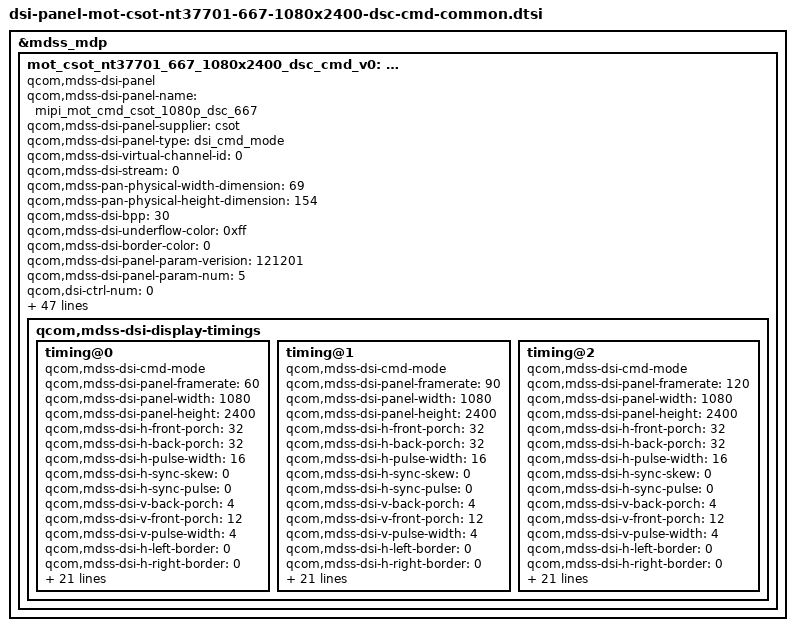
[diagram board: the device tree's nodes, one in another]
/* Copyright (c) 2019-2020, The Linux Foundation. All rights reserved.
 *
 * This program is free software; you can redistribute it and/or modify
 * it under the terms of the GNU General Public License version 2 and
 * only version 2 as published by the Free Software Foundation.
 *
 * This program is distributed in the hope that it will be useful,
 * but WITHOUT ANY WARRANTY; without even the implied warranty of
 * MERCHANTABILITY or FITNESS FOR A PARTICULAR PURPOSE.  See the
 * GNU General Public License for more details.
 */
&mdss_mdp {
mot_csot_nt37701_667_1080x2400_dsc_cmd_v0: qcom,mdss_dsi_mot_csot_nt37701_667_1080x2400_dsc_cmd_v0 {
compatible = "qcom,mdss-dsi-panel";
qcom,mdss-dsi-panel-name = "mipi_mot_cmd_csot_1080p_dsc_667";
qcom,mdss-dsi-panel-supplier = "csot";
qcom,mdss-dsi-panel-type = "dsi_cmd_mode";
qcom,mdss-dsi-virtual-channel-id = <0>;
qcom,mdss-dsi-stream = <0>;
qcom,mdss-pan-physical-width-dimension = <69>;
qcom,mdss-pan-physical-height-dimension = <154>;
qcom,mdss-dsi-bpp = <30>;
qcom,mdss-dsi-underflow-color = <0xff>;
qcom,mdss-dsi-border-color = <0>;
qcom,mdss-dsi-panel-param-verision = <121201>;
qcom,mdss-dsi-panel-param-num = <5>;

qcom,dsi-ctrl-num = <0>;
qcom,dsi-phy-num = <0>;

qcom,mdss-dsi-traffic-mode = "burst_mode";
qcom,mdss-dsi-bllp-eof-power-mode;
qcom,mdss-dsi-bllp-power-mode;
qcom,mdss-dsi-lane-0-state;
qcom,mdss-dsi-lane-1-state;
qcom,mdss-dsi-lane-2-state;
qcom,mdss-dsi-lane-3-state;

qcom,mdss-dsi-dma-trigger = "trigger_sw";
qcom,mdss-dsi-mdp-trigger = "none";
qcom,mdss-dsi-reset-sequence = <0 11>, <1 1>, <0 1>, <1 11>;
qcom,mdss-dsi-lp11-init;
qcom,mdss-dsi-tx-eot-append;
qcom,mdss-dsi-te-pin-select = <1>;
qcom,mdss-dsi-te-dcs-command = <1>;

qcom,mdss-dsi-te-using-te-pin;

qcom,bklt-dcs-2bytes-enabled;
qcom,mdss-dsi-bl-min-level = <3>;
qcom,mdss-dsi-bl-max-level = <2047>;
qcom,mdss-dsi-bl-pmic-control-type = "bl_ctrl_dcs";

qcom,mdss-dsi-panel-hdr-enabled;
qcom,mdss-dsi-panel-hdr-color-primaries = <14500 15500 32000
	        17000 15500 30000 8000 3000>;
qcom,mdss-dsi-panel-peak-brightness = <4200000>;

qcom,mdss-dsi-panel-blackness-level = <3230>;
qcom,mdss-dsi-hbm-on-command = [
		39 01 00 00 00 00 03 51 0F FF];
qcom,mdss-dsi-hbm-off-command = [
		39 01 00 00 00 00 03 51 07 FF];

qcom,mdss-dsi-color-vbt-command = [
                15 01 00 00 00 00 02 55 90];
qcom,mdss-dsi-color-vbt-command-state = "dsi_lp_mode";
qcom,mdss-dsi-color-std-command = [
                15 01 00 00 00 00 02 55 90];
qcom,mdss-dsi-color-std-command-state = "dsi_lp_mode";
qcom,mdss-dsi-color-game-command = [
		15 01 00 00 00 00 02 55 80];
qcom,mdss-dsi-color-game-command-state = "dsi_lp_mode";
qcom,mdss-dsi-color-none-command = [
		15 01 00 00 00 00 02 55 90];
qcom,mdss-dsi-color-none-command-state = "dsi_lp_mode";

//qcom,mdss-dsi-acl-on-command = [
//		39 01 00 00 00 00 06 F0 55 AA 52 08 00
//		15 00 00 00 00 00 02 B0 0C
//		15 01 00 00 00 00 02 55 05];
//qcom,mdss-dsi-acl-off-command = [
//		15 01 00 00 00 00 02 55 00];


qcom,mdss-dsi-display-timings {
	timing@0{
		qcom,mdss-dsi-cmd-mode;
		qcom,mdss-dsi-panel-framerate = <60>;
		qcom,mdss-dsi-panel-width = <1080>;
		qcom,mdss-dsi-panel-height = <2400>;
		qcom,mdss-dsi-h-front-porch = <32>;
		qcom,mdss-dsi-h-back-porch = <32>;
		qcom,mdss-dsi-h-pulse-width = <16>;
		qcom,mdss-dsi-h-sync-skew = <0>;
		qcom,mdss-dsi-h-sync-pulse = <0>;
		qcom,mdss-dsi-v-back-porch = <4>;
		qcom,mdss-dsi-v-front-porch = <12>;
		qcom,mdss-dsi-v-pulse-width = <4>;
		qcom,mdss-dsi-h-left-border = <0>;
		qcom,mdss-dsi-h-right-border = <0>;
		qcom,mdss-dsi-v-top-border = <0>;
		qcom,mdss-dsi-v-bottom-border = <0>;
		qcom,mdss-dsi-panel-jitter = <0x20 0xa>; /* 90fps +/- 2 */
		qcom,mdss-dsi-timing-switch-command = [
			15 01 00 00 14 00 02 2F 01 //01:60 02:90 03:120
			15 01 00 00 00 00 02 8B 00
		];

		qcom,mdss-dsi-on-command = [
                        39 01 00 00 00 00 06 F0 55 AA 52 08 07
                        39 01 00 00 00 00 02 6F 00
                        39 01 00 00 00 00 16 C5 21 00 03 49 03 49 00 00 3F FF 41 76 3F FF 41 76 00 00 0A CA D1
                        39 01 00 00 00 00 02 6F 15
                        39 01 00 00 00 00 10 C5 01 FE 15 02 1B 32 33 80 03 49 0F E3 E3 00 00
                        39 01 00 00 00 00 02 6F 24
                        39 01 00 00 00 00 08 C5 00 00 00 00 00 00 00
                        39 01 00 00 00 00 02 6F 00
                        39 01 00 00 00 00 16 C6 27 00 03 49 03 49 00 00 00 00 00 00 3F FF 41 76 00 00 00 00 00
                        39 01 00 00 00 00 02 6F 15
                        39 01 00 00 00 00 10 C6 02 1C 15 02 39 32 33 80 00 00 03 1D E3 00 00
                        39 01 00 00 00 00 02 6F 24
                        39 01 00 00 00 00 08 C6 00 00 00 00 00 00 00
                        39 01 00 00 00 00 02 6F 00
                        39 01 00 00 00 00 16 C7 2D 00 03 84 03 49 00 00 3F FF 34 18 00 00 00 00 80 00 00 00 00
                        39 01 00 00 00 00 02 6F 15
                        39 01 00 00 00 00 10 C7 01 FE 33 02 1B 51 33 50 00 00 0C E2 1D 00 00
                        39 01 00 00 00 00 02 6F 24
                        39 01 00 00 00 00 08 C7 00 00 00 00 00 00 00
                        39 01 00 00 00 00 02 6F 00
                        39 01 00 00 00 00 16 C8 2B 00 03 84 03 49 00 00 00 00 00 00 00 00 00 00 FF FF F4 73 5C
                        39 01 00 00 00 00 02 6F 15
                        39 01 00 00 00 00 10 C8 02 1C 33 02 39 51 33 5F FC 9A 00 1E 1D 00 00
                        39 01 00 00 00 00 02 6F 24
                        39 01 00 00 00 00 08 C8 00 00 00 00 00 00 00

                        39 01 00 00 00 00 06 F0 55 AA 52 08 00
                        39 01 00 00 00 00 02 6F 02
                        39 01 00 00 00 00 03 EC 81 C2
			39 01 00 00 00 00 19 CC 40 54 5A 60 66 6A 6C 6C 68 62 5B 53 4D 48 44 41 40 50 60 70 58 68 74 74
			39 01 00 00 00 00 12 CD 40 40 40 40 40 40 40 40 40 45 49 4C 4B 48 44 41 40
			39 01 00 00 00 00 13 CE 00 40 40 40 40 40 40 40 40 40 40 40 40 40 40 40 40 40
			39 01 00 00 00 00 12 CF 40 40 40 40 40 40 40 40 40 40 40 40 40 40 40 40 40
			39 01 00 00 00 00 07 D0 00 00 FC 74 0C 1D
			39 01 00 00 00 00 2E D1 50 50 50 50 50 50 50 50 50 50 50 50 50 50 50 50 50 50 50 50 50 50 50 50 00 00 00 00 00 00 00 00 00 00 00 00 00 06 0C 03 09 0F 68 88 00
			39 01 00 00 00 00 07 D3 30 52 74 74 50 10
			39 01 00 00 00 00 1A D4 0F 77 74 0F 00 14 0F 18 1F 05 0D 14 03 07 0A A0 75 FA 10 44 12 00 00 80 00
			39 01 00 00 00 00 14 D7 30 40 40 40 40 40 40 40 40 40 40 40 40 40 40 40 40 40 40
			39 01 00 00 00 00 02 55 90
			39 01 00 00 00 00 06 F0 55 AA 52 08 07
			39 01 00 00 00 00 03 c0 01 0f

			39 01 00 00 00 00 06 F0 55 AA 52 08 01
			39 01 00 00 00 00 02 6f 01
			39 01 00 00 00 00 02 cd 81

			39 01 00 00 00 00 06 F0 55 AA 52 08 08
			39 01 00 00 00 00 03 C0 0F 7E//demura scale

			15 01 00 00 00 00 02 03 01
			15 01 00 00 00 00 02 90 01
			39 01 00 00 00 00 13 91 AB 28 00 0C C2 00 03 1C 01 7E 00 0F 08 BB 04 3D 10 F0
			15 01 00 00 00 00 02 2C 00 //dsc config 10bit

			39 01 00 00 00 00 03 51 00 00
			15 01 00 00 00 00 02 53 20
			15 01 00 00 00 00 02 35 00 //te enable

			39 01 00 00 00 00 05 2A 00 00 04 37
			39 01 00 00 00 00 05 2B 00 00 09 5F

			15 01 00 00 00 00 02 2F 01 //01:60 02:90 03:120
			15 01 00 00 00 00 02 8B 00

			05 01 00 00 6e 00 01 11
			05 01 00 00 00 00 01 29];	/* display on */
		qcom,mdss-dsi-off-command = [
			05 01 00 00 00 00 01 28		/* display_off */
			05 01 00 00 78 00 01 10];	/* enter sleep mode */

		qcom,mdss-dsi-on-command-state = "dsi_lp_mode";
		qcom,mdss-dsi-off-command-state = "dsi_lp_mode";
		qcom,mdss-dsi-timing-switch-command-state =
			"dsi_lp_mode";
		qcom,compression-mode = "dsc";
		/* Why QCOM doesn't use this, even it used 2 encoder
		 * as for that dsi_sw43404_amoled_cmd, for ex */
		/* qcom,mdss-dsc-encoders = <2>; */
		qcom,mdss-dsc-version = <0x11>;
		qcom,mdss-dsc-slice-height = <12>;
		qcom,mdss-dsc-slice-width = <1080>;
		qcom,mdss-dsc-slice-per-pkt = <1>;
		qcom,mdss-dsc-bit-per-component = <10>;
		qcom,mdss-dsc-bit-per-pixel = <8>;
		qcom,mdss-dsc-block-prediction-enable;
	};

	timing@1{
		qcom,mdss-dsi-cmd-mode;
		qcom,mdss-dsi-panel-framerate = <90>;
		qcom,mdss-dsi-panel-width = <1080>;
		qcom,mdss-dsi-panel-height = <2400>;
		qcom,mdss-dsi-h-front-porch = <32>;
		qcom,mdss-dsi-h-back-porch = <32>;
		qcom,mdss-dsi-h-pulse-width = <16>;
		qcom,mdss-dsi-h-sync-skew = <0>;
		qcom,mdss-dsi-h-sync-pulse = <0>;
		qcom,mdss-dsi-v-back-porch = <4>;
		qcom,mdss-dsi-v-front-porch = <12>;
		qcom,mdss-dsi-v-pulse-width = <4>;
		qcom,mdss-dsi-h-left-border = <0>;
		qcom,mdss-dsi-h-right-border = <0>;
		qcom,mdss-dsi-v-top-border = <0>;
		qcom,mdss-dsi-v-bottom-border = <0>;
		qcom,mdss-dsi-panel-jitter = <0x20 0xa>; /* 90fps +/- 2 */
		qcom,mdss-dsi-timing-switch-command = [
			15 01 00 00 0b 00 02 2F 02 //01:60 02:90 03:120
			15 01 00 00 00 00 02 8B 00
		];

		qcom,mdss-dsi-on-command = [
                        39 01 00 00 00 00 06 F0 55 AA 52 08 07
                        39 01 00 00 00 00 02 6F 00
                        39 01 00 00 00 00 16 C5 21 00 03 49 03 49 00 00 3F FF 41 76 3F FF 41 76 00 00 0A CA D1
                        39 01 00 00 00 00 02 6F 15
                        39 01 00 00 00 00 10 C5 01 FE 15 02 1B 32 33 80 03 49 0F E3 E3 00 00
                        39 01 00 00 00 00 02 6F 24
                        39 01 00 00 00 00 08 C5 00 00 00 00 00 00 00
                        39 01 00 00 00 00 02 6F 00
                        39 01 00 00 00 00 16 C6 27 00 03 49 03 49 00 00 00 00 00 00 3F FF 41 76 00 00 00 00 00
                        39 01 00 00 00 00 02 6F 15
                        39 01 00 00 00 00 10 C6 02 1C 15 02 39 32 33 80 00 00 03 1D E3 00 00
                        39 01 00 00 00 00 02 6F 24
                        39 01 00 00 00 00 08 C6 00 00 00 00 00 00 00
                        39 01 00 00 00 00 02 6F 00
                        39 01 00 00 00 00 16 C7 2D 00 03 84 03 49 00 00 3F FF 34 18 00 00 00 00 80 00 00 00 00
                        39 01 00 00 00 00 02 6F 15
                        39 01 00 00 00 00 10 C7 01 FE 33 02 1B 51 33 50 00 00 0C E2 1D 00 00
                        39 01 00 00 00 00 02 6F 24
                        39 01 00 00 00 00 08 C7 00 00 00 00 00 00 00
                        39 01 00 00 00 00 02 6F 00
                        39 01 00 00 00 00 16 C8 2B 00 03 84 03 49 00 00 00 00 00 00 00 00 00 00 FF FF F4 73 5C
                        39 01 00 00 00 00 02 6F 15
                        39 01 00 00 00 00 10 C8 02 1C 33 02 39 51 33 5F FC 9A 00 1E 1D 00 00
                        39 01 00 00 00 00 02 6F 24
                        39 01 00 00 00 00 08 C8 00 00 00 00 00 00 00

                        39 01 00 00 00 00 06 F0 55 AA 52 08 00
                        39 01 00 00 00 00 02 6F 02
                        39 01 00 00 00 00 03 EC 81 C2
			39 01 00 00 00 00 19 CC 40 54 5A 60 66 6A 6C 6C 68 62 5B 53 4D 48 44 41 40 50 60 70 58 68 74 74
			39 01 00 00 00 00 12 CD 40 40 40 40 40 40 40 40 40 45 49 4C 4B 48 44 41 40
			39 01 00 00 00 00 13 CE 00 40 40 40 40 40 40 40 40 40 40 40 40 40 40 40 40 40
			39 01 00 00 00 00 12 CF 40 40 40 40 40 40 40 40 40 40 40 40 40 40 40 40 40
			39 01 00 00 00 00 07 D0 00 00 FC 74 0C 1D
			39 01 00 00 00 00 2E D1 50 50 50 50 50 50 50 50 50 50 50 50 50 50 50 50 50 50 50 50 50 50 50 50 00 00 00 00 00 00 00 00 00 00 00 00 00 06 0C 03 09 0F 68 88 00
			39 01 00 00 00 00 07 D3 30 52 74 74 50 10
			39 01 00 00 00 00 1A D4 0F 77 74 0F 00 14 0F 18 1F 05 0D 14 03 07 0A A0 75 FA 10 44 12 00 00 80 00
			39 01 00 00 00 00 14 D7 30 40 40 40 40 40 40 40 40 40 40 40 40 40 40 40 40 40 40
			39 01 00 00 00 00 02 55 90
			39 01 00 00 00 00 06 F0 55 AA 52 08 07
			39 01 00 00 00 00 03 c0 01 0f

			39 01 00 00 00 00 06 F0 55 AA 52 08 01
			39 01 00 00 00 00 02 6f 01
			39 01 00 00 00 00 02 cd 81

			39 01 00 00 00 00 06 F0 55 AA 52 08 08
			39 01 00 00 00 00 03 C0 0F 7E//demura scale

			15 01 00 00 00 00 02 03 01
			15 01 00 00 00 00 02 90 01
			39 01 00 00 00 00 13 91 AB 28 00 0C C2 00 03 1C 01 7E 00 0F 08 BB 04 3D 10 F0
			15 01 00 00 00 00 02 2C 00 //dsc config 10bit

			39 01 00 00 00 00 03 51 00 00
			15 01 00 00 00 00 02 53 20
			15 01 00 00 00 00 02 35 00 //te enable

			39 01 00 00 00 00 05 2A 00 00 04 37
			39 01 00 00 00 00 05 2B 00 00 09 5F

			15 01 00 00 00 00 02 2F 02 //01:60 02:90 03:120
			15 01 00 00 00 00 02 8B 00

			05 01 00 00 56 00 01 11
			05 01 00 00 00 00 01 29];	/* display on */
		qcom,mdss-dsi-off-command = [
			05 01 00 00 00 00 01 28		/* display_off */
			05 01 00 00 78 00 01 10];	/* enter sleep mode */

		qcom,mdss-dsi-on-command-state = "dsi_lp_mode";
		qcom,mdss-dsi-off-command-state = "dsi_lp_mode";
		qcom,mdss-dsi-timing-switch-command-state =
			"dsi_lp_mode";
		qcom,compression-mode = "dsc";
		/* Why QCOM doesn't use this, even it used 2 encoder
		 * as for that dsi_sw43404_amoled_cmd, for ex */
		/* qcom,mdss-dsc-encoders = <2>; */
		qcom,mdss-dsc-version = <0x11>;
		qcom,mdss-dsc-slice-height = <12>;
		qcom,mdss-dsc-slice-width = <1080>;
		qcom,mdss-dsc-slice-per-pkt = <1>;
		qcom,mdss-dsc-bit-per-component = <10>;
		qcom,mdss-dsc-bit-per-pixel = <8>;
		qcom,mdss-dsc-block-prediction-enable;
	};
	timing@2{
		qcom,mdss-dsi-cmd-mode;
		qcom,mdss-dsi-panel-framerate = <120>;
		qcom,mdss-dsi-panel-width = <1080>;
		qcom,mdss-dsi-panel-height = <2400>;
		qcom,mdss-dsi-h-front-porch = <32>;
		qcom,mdss-dsi-h-back-porch = <32>;
		qcom,mdss-dsi-h-pulse-width = <16>;
		qcom,mdss-dsi-h-sync-skew = <0>;
		qcom,mdss-dsi-h-sync-pulse = <0>;
		qcom,mdss-dsi-v-back-porch = <4>;
		qcom,mdss-dsi-v-front-porch = <12>;
		qcom,mdss-dsi-v-pulse-width = <4>;
		qcom,mdss-dsi-h-left-border = <0>;
		qcom,mdss-dsi-h-right-border = <0>;
		qcom,mdss-dsi-v-top-border = <0>;
		qcom,mdss-dsi-v-bottom-border = <0>;
		qcom,mdss-dsi-panel-jitter = <0x20 0xa>; /* 90fps +/- 2 */
		qcom,mdss-dsi-timing-switch-command = [
			15 01 00 00 08 00 02 2F 03 //01:60 02:90 03:120
			15 01 00 00 00 00 02 8B 00
		];

		qcom,mdss-dsi-on-command = [
                        39 01 00 00 00 00 06 F0 55 AA 52 08 07
                        39 01 00 00 00 00 02 6F 00
                        39 01 00 00 00 00 16 C5 21 00 03 49 03 49 00 00 3F FF 41 76 3F FF 41 76 00 00 0A CA D1
                        39 01 00 00 00 00 02 6F 15
                        39 01 00 00 00 00 10 C5 01 FE 15 02 1B 32 33 80 03 49 0F E3 E3 00 00
                        39 01 00 00 00 00 02 6F 24
                        39 01 00 00 00 00 08 C5 00 00 00 00 00 00 00
                        39 01 00 00 00 00 02 6F 00
                        39 01 00 00 00 00 16 C6 27 00 03 49 03 49 00 00 00 00 00 00 3F FF 41 76 00 00 00 00 00
                        39 01 00 00 00 00 02 6F 15
                        39 01 00 00 00 00 10 C6 02 1C 15 02 39 32 33 80 00 00 03 1D E3 00 00
                        39 01 00 00 00 00 02 6F 24
                        39 01 00 00 00 00 08 C6 00 00 00 00 00 00 00
                        39 01 00 00 00 00 02 6F 00
                        39 01 00 00 00 00 16 C7 2D 00 03 84 03 49 00 00 3F FF 34 18 00 00 00 00 80 00 00 00 00
                        39 01 00 00 00 00 02 6F 15
                        39 01 00 00 00 00 10 C7 01 FE 33 02 1B 51 33 50 00 00 0C E2 1D 00 00
                        39 01 00 00 00 00 02 6F 24
                        39 01 00 00 00 00 08 C7 00 00 00 00 00 00 00
                        39 01 00 00 00 00 02 6F 00
                        39 01 00 00 00 00 16 C8 2B 00 03 84 03 49 00 00 00 00 00 00 00 00 00 00 FF FF F4 73 5C
                        39 01 00 00 00 00 02 6F 15
                        39 01 00 00 00 00 10 C8 02 1C 33 02 39 51 33 5F FC 9A 00 1E 1D 00 00
                        39 01 00 00 00 00 02 6F 24
                        39 01 00 00 00 00 08 C8 00 00 00 00 00 00 00

                        39 01 00 00 00 00 06 F0 55 AA 52 08 00
                        39 01 00 00 00 00 02 6F 02
                        39 01 00 00 00 00 03 EC 81 C2
			39 01 00 00 00 00 19 CC 40 54 5A 60 66 6A 6C 6C 68 62 5B 53 4D 48 44 41 40 50 60 70 58 68 74 74
			39 01 00 00 00 00 12 CD 40 40 40 40 40 40 40 40 40 45 49 4C 4B 48 44 41 40
			39 01 00 00 00 00 13 CE 00 40 40 40 40 40 40 40 40 40 40 40 40 40 40 40 40 40
			39 01 00 00 00 00 12 CF 40 40 40 40 40 40 40 40 40 40 40 40 40 40 40 40 40
			39 01 00 00 00 00 07 D0 00 00 FC 74 0C 1D
			39 01 00 00 00 00 2E D1 50 50 50 50 50 50 50 50 50 50 50 50 50 50 50 50 50 50 50 50 50 50 50 50 00 00 00 00 00 00 00 00 00 00 00 00 00 06 0C 03 09 0F 68 88 00
			39 01 00 00 00 00 07 D3 30 52 74 74 50 10
			39 01 00 00 00 00 1A D4 0F 77 74 0F 00 14 0F 18 1F 05 0D 14 03 07 0A A0 75 FA 10 44 12 00 00 80 00
			39 01 00 00 00 00 14 D7 30 40 40 40 40 40 40 40 40 40 40 40 40 40 40 40 40 40 40
			39 01 00 00 00 00 02 55 90
			39 01 00 00 00 00 06 F0 55 AA 52 08 07
			39 01 00 00 00 00 03 c0 01 0f

			39 01 00 00 00 00 06 F0 55 AA 52 08 01
			39 01 00 00 00 00 02 6f 01
			39 01 00 00 00 00 02 cd 81

			39 01 00 00 00 00 06 F0 55 AA 52 08 08
			39 01 00 00 00 00 03 C0 0F 7E//demura scale

			15 01 00 00 00 00 02 03 01
			15 01 00 00 00 00 02 90 01
			39 01 00 00 00 00 13 91 AB 28 00 0C C2 00 03 1C 01 7E 00 0F 08 BB 04 3D 10 F0
			15 01 00 00 00 00 02 2C 00 //dsc config 10bit

			39 01 00 00 00 00 03 51 00 00
			15 01 00 00 00 00 02 53 20
			15 01 00 00 00 00 02 35 00 //te enable

			39 01 00 00 00 00 05 2A 00 00 04 37
			39 01 00 00 00 00 05 2B 00 00 09 5F

			15 01 00 00 00 00 02 2F 03 //01:60 02:90 03:120
			15 01 00 00 00 00 02 8B 00

			05 01 00 00 56 00 01 11
			05 01 00 00 00 00 01 29];	/* display on */
		qcom,mdss-dsi-off-command = [
			05 01 00 00 00 00 01 28		/* display_off */
			05 01 00 00 78 00 01 10];	/* enter sleep mode */

		qcom,mdss-dsi-on-command-state = "dsi_lp_mode";
		qcom,mdss-dsi-off-command-state = "dsi_lp_mode";
		qcom,mdss-dsi-timing-switch-command-state =
			"dsi_lp_mode";
		qcom,compression-mode = "dsc";
		/* Why QCOM doesn't use this, even it used 2 encoder
		 * as for that dsi_sw43404_amoled_cmd, for ex */
		/* qcom,mdss-dsc-encoders = <2>; */
		qcom,mdss-dsc-version = <0x11>;
		qcom,mdss-dsc-slice-height = <12>;
		qcom,mdss-dsc-slice-width = <1080>;
		qcom,mdss-dsc-slice-per-pkt = <1>;
		qcom,mdss-dsc-bit-per-component = <10>;
		qcom,mdss-dsc-bit-per-pixel = <8>;
		qcom,mdss-dsc-block-prediction-enable;
	};


};

};

};
